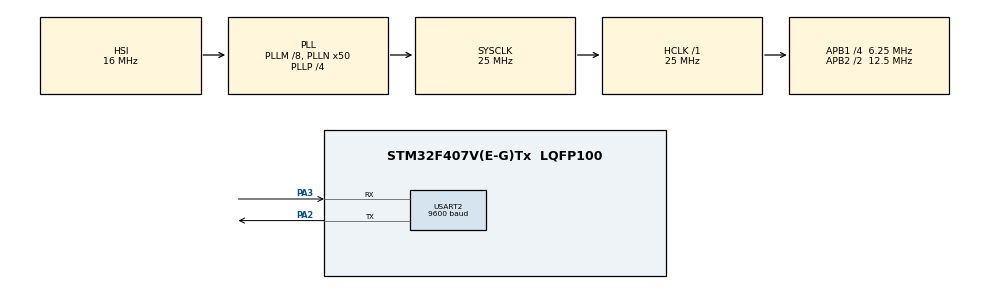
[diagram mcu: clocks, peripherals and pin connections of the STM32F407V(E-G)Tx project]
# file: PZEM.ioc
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Mcu.Family=STM32F4
Mcu.Name=STM32F407V(E-G)Tx
Mcu.Package=LQFP100
NVIC.PriorityGroup=NVIC_PRIORITYGROUP_0
NVIC.USART2_IRQn=true\:0\:0\:false\:false\:true\:true\:true\:true
PA2.Mode=Asynchronous
PA2.Signal=USART2_TX
PA3.Mode=Asynchronous
PA3.Signal=USART2_RX
ProjectManager.HeapSize=0x200
ProjectManager.StackSize=0x400
ProjectManager.TargetToolchain=STM32CubeIDE
RCC.48MHZClocksFreq_Value=14285714.285714285
RCC.AHBFreq_Value=25000000
RCC.APB1CLKDivider=RCC_HCLK_DIV4
RCC.APB1Freq_Value=6250000
RCC.APB1TimFreq_Value=12500000
RCC.APB2CLKDivider=RCC_HCLK_DIV2
RCC.APB2Freq_Value=12500000
RCC.APB2TimFreq_Value=25000000
RCC.CortexFreq_Value=25000000
RCC.HCLKFreq_Value=25000000
RCC.HSE_VALUE=8000000
RCC.HSI_VALUE=16000000
RCC.LSE_VALUE=32768
RCC.PLLM=8
RCC.PLLN=50
RCC.PLLP=RCC_PLLP_DIV4
RCC.PLLQ=7
RCC.SYSCLKFreq_VALUE=25000000
RCC.SYSCLKSource=RCC_SYSCLKSOURCE_PLLCLK
RCC.VCOOutputFreq_Value=100000000
USART2.BaudRate=9600
USART2.VirtualMode=VM_ASYNC
board=STM32F407G-DISC1

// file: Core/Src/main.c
/* USER CODE BEGIN Header */
/**
  ******************************************************************************
  * @file           : main.c
  * @brief          : Main program body
  ******************************************************************************
  * @attention
  *
  * Copyright (c) 2025 STMicroelectronics.
  * All rights reserved.
  *
  * This software is licensed under terms that can be found in the LICENSE file
  * in the root directory of this software component.
  * If no LICENSE file comes with this software, it is provided AS-IS.
  *
  ******************************************************************************
  */
/* USER CODE END Header */
#include "main.h"

/* USER CODE BEGIN Includes */
#include <stdbool.h>
/* USER CODE END Includes */

/* USER CODE BEGIN PD */
#define PZEM_SLAVE_ADDR 0x01
/* USER CODE END PD */

UART_HandleTypeDef huart2;

/* USER CODE BEGIN PV */
float voltage_value; float current_value; float power_value; float energy_value;
/* USER CODE END PV */

void SystemClock_Config(void);
static void MX_GPIO_Init(void);
static void MX_USART2_UART_Init(void);
/* USER CODE BEGIN PFP */
uint16_t read_pzem_register(uint16_t reg_addr);
bool check_crc(uint8_t *data, uint16_t length);
uint16_t calculate_crc(uint8_t *data, uint16_t length);
/* USER CODE END PFP */

int main(void)
{

  /* MCU Configuration--------------------------------------------------------*/

  /* Reset of all peripherals, Initializes the Flash interface and the Systick. */
  HAL_Init();

  /* Configure the system clock */
  SystemClock_Config();

  /* Initialize all configured peripherals */
  MX_GPIO_Init();
  MX_USART2_UART_Init();
  /* USER CODE BEGIN 2 */

  uint16_t calculate_crc(uint8_t *data, uint16_t length)
   	  {
   	   uint16_t crc = 0xFFFF;
   	  for (uint16_t i = 0; i < length; i++)
   	  {
   	  crc ^= data[i];
   	  for (uint8_t j = 0; j < 8; j++)
   	  {
   	  if (crc & 0x0001)
   	  {
   	  crc >>= 1; crc ^= 0xA001;
   	  }
   	  else
   	  {
   	  crc >>= 1;
   	  }
   	  }
   	  }
   	  return crc;
   	  }

  bool check_crc(uint8_t *data, uint16_t length)
 	  {
 	  uint16_t received_crc = (data[length - 1] << 8) | data[length - 2];
 	  uint16_t calculated_crc = calculate_crc(data, length - 2);
 	  return received_crc == calculated_crc;
 	   }

  uint16_t read_pzem_register(uint16_t reg_addr)
  {
  uint8_t tx_data[8];
  uint8_t rx_data[7];
  uint16_t result = 0;
  tx_data[0] = PZEM_SLAVE_ADDR;
  tx_data[1] = 0x04;
  tx_data[2] = (reg_addr >> 8) & 0xFF;
  tx_data[3] = reg_addr & 0xFF;
  tx_data[4] = 0x00;
  tx_data[5] = 0x01;
  uint16_t crc = calculate_crc(tx_data, 6);
  tx_data[6] = crc & 0xFF; // CRC low byte
  tx_data[7] = (crc >> 8) & 0xFF;
  HAL_UART_Transmit(&huart2, tx_data, 8, 100);
  HAL_UART_Receive(&huart2, rx_data, 7, 100);
  if (check_crc(rx_data, 7))
  {
  result = (rx_data[3] << 8) | rx_data[4];
  }
  return result;
  }
  /* USER CODE END 2 */

  /* Infinite loop */
  /* USER CODE BEGIN WHILE */
  while (1)
  {
	  uint16_t voltage = read_pzem_register(0x0000);
	  	  uint16_t current_low = read_pzem_register(0x0001);
	  	  uint16_t current_high = read_pzem_register(0x0002);
	  	  uint16_t power_low = read_pzem_register(0x0003);
	  	  uint16_t power_high = read_pzem_register(0x0004);
	  	  uint16_t energy_low = read_pzem_register(0x0005);
	  	  uint16_t energy_high = read_pzem_register(0x0006);
	  	  voltage_value = voltage * 0.1;
	  	  current_value = (current_high << 16 | current_low) * 0.001;
	  	  power_value = (power_high << 16 | power_low) * 0.1;
	  	  energy_value = (energy_high << 16 | energy_low) * 1.0;
    /* USER CODE END WHILE */

}
}

void SystemClock_Config(void)
{
  RCC_OscInitTypeDef RCC_OscInitStruct = {0};
  RCC_ClkInitTypeDef RCC_ClkInitStruct = {0};

  /** Configure the main internal regulator output voltage
  */
  __HAL_RCC_PWR_CLK_ENABLE();
  __HAL_PWR_VOLTAGESCALING_CONFIG(PWR_REGULATOR_VOLTAGE_SCALE1);

  /** Initializes the RCC Oscillators according to the specified parameters
  * in the RCC_OscInitTypeDef structure.
  */
  RCC_OscInitStruct.OscillatorType = RCC_OSCILLATORTYPE_HSI;
  RCC_OscInitStruct.HSIState = RCC_HSI_ON;
  RCC_OscInitStruct.HSICalibrationValue = RCC_HSICALIBRATION_DEFAULT;
  RCC_OscInitStruct.PLL.PLLState = RCC_PLL_ON;
  RCC_OscInitStruct.PLL.PLLSource = RCC_PLLSOURCE_HSI;
  RCC_OscInitStruct.PLL.PLLM = 8;
  RCC_OscInitStruct.PLL.PLLN = 50;
  RCC_OscInitStruct.PLL.PLLP = RCC_PLLP_DIV4;
  RCC_OscInitStruct.PLL.PLLQ = 7;
  if (HAL_RCC_OscConfig(&RCC_OscInitStruct) != HAL_OK)
  {
    Error_Handler();
  }

  /** Initializes the CPU, AHB and APB buses clocks
  */
  RCC_ClkInitStruct.ClockType = RCC_CLOCKTYPE_HCLK|RCC_CLOCKTYPE_SYSCLK
                              |RCC_CLOCKTYPE_PCLK1|RCC_CLOCKTYPE_PCLK2;
  RCC_ClkInitStruct.SYSCLKSource = RCC_SYSCLKSOURCE_PLLCLK;
  RCC_ClkInitStruct.AHBCLKDivider = RCC_SYSCLK_DIV1;
  RCC_ClkInitStruct.APB1CLKDivider = RCC_HCLK_DIV4;
  RCC_ClkInitStruct.APB2CLKDivider = RCC_HCLK_DIV2;

  if (HAL_RCC_ClockConfig(&RCC_ClkInitStruct, FLASH_LATENCY_0) != HAL_OK)
  {
    Error_Handler();
  }
}

static void MX_USART2_UART_Init(void)
{

  huart2.Instance = USART2;
  huart2.Init.BaudRate = 9600;
  huart2.Init.WordLength = UART_WORDLENGTH_8B;
  huart2.Init.StopBits = UART_STOPBITS_1;
  huart2.Init.Parity = UART_PARITY_NONE;
  huart2.Init.Mode = UART_MODE_TX_RX;
  huart2.Init.HwFlowCtl = UART_HWCONTROL_NONE;
  huart2.Init.OverSampling = UART_OVERSAMPLING_16;
  if (HAL_UART_Init(&huart2) != HAL_OK)
  {
    Error_Handler();
  }

}

static void MX_GPIO_Init(void)
{

  /* GPIO Ports Clock Enable */
  __HAL_RCC_GPIOA_CLK_ENABLE();

}

void Error_Handler(void)
{
  __disable_irq();
  while (1)
  {
  }
}
